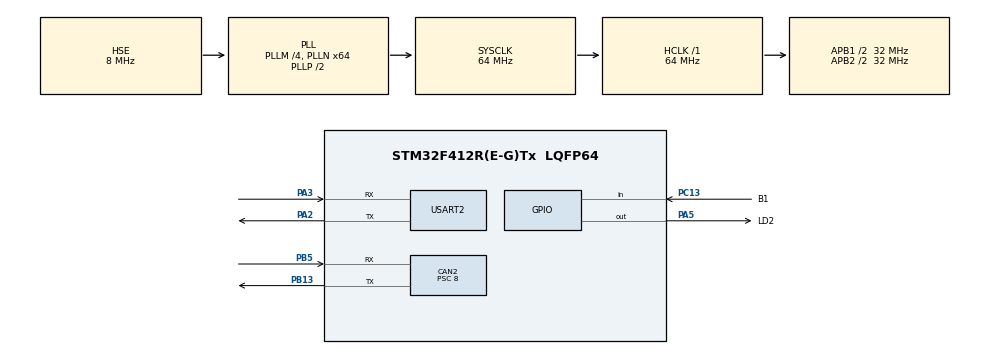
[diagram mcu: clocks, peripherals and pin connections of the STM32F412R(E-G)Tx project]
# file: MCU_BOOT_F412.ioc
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CAN2.ABOM=ENABLE
CAN2.BS1=CAN_BS1_13TQ
CAN2.BS2=CAN_BS2_2TQ
CAN2.CalculateBaudRate=250000
CAN2.CalculateTimeBit=4000
CAN2.CalculateTimeQuantum=250.0
CAN2.NART=DISABLE
CAN2.Prescaler=8
Mcu.Family=STM32F4
Mcu.Name=STM32F412R(E-G)Tx
Mcu.Package=LQFP64
NVIC.PriorityGroup=NVIC_PRIORITYGROUP_4
PA13.Mode=Serial_Wire
PA13.Signal=SYS_JTMS-SWDIO
PA14.Mode=Serial_Wire
PA14.Signal=SYS_JTCK-SWCLK
PA2.Mode=Asynchronous
PA2.Signal=USART2_TX
PA3.Mode=Asynchronous
PA3.Signal=USART2_RX
PA5.GPIO_Label=LD2
PA5.Signal=GPIO_Output
PB13.Mode=CAN_Activate
PB13.Signal=CAN2_TX
PB5.Mode=CAN_Activate
PB5.Signal=CAN2_RX
PC13.GPIO_Label=B1
PC13.GPIO_PuPd=GPIO_PULLUP
PC13.Signal=GPIO_Input
PH0\ -\ OSC_IN.Mode=HSE-External-Oscillator
PH0\ -\ OSC_IN.Signal=RCC_OSC_IN
PH1\ -\ OSC_OUT.Mode=HSE-External-Oscillator
PH1\ -\ OSC_OUT.Signal=RCC_OSC_OUT
ProjectManager.HeapSize=0x200
ProjectManager.StackSize=0x400
ProjectManager.TargetToolchain=STM32CubeIDE
RCC.AHBFreq_Value=64000000
RCC.APB1CLKDivider=RCC_HCLK_DIV2
RCC.APB1Freq_Value=32000000
RCC.APB1TimFreq_Value=64000000
RCC.APB2CLKDivider=RCC_HCLK_DIV2
RCC.APB2Freq_Value=32000000
RCC.APB2TimFreq_Value=64000000
RCC.CortexFreq_Value=64000000
RCC.HCLKFreq_Value=64000000
RCC.HSE_VALUE=8000000
RCC.PLLI2SM=2
RCC.PLLI2SN=64
RCC.PLLM=4
RCC.PLLN=64
RCC.PLLSourceVirtual=RCC_PLLSOURCE_HSE
RCC.SYSCLKFreq_VALUE=64000000
RCC.SYSCLKSource=RCC_SYSCLKSOURCE_PLLCLK
RCC.USBFreq_Value=64000000
RCC.VCOOutputFreq_Value=128000000
USART2.VirtualMode=VM_ASYNC
board=custom

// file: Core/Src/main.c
/* USER CODE BEGIN Header */
/**
  ******************************************************************************
  * @file           : main.c
  * @brief          : Main program body
  ******************************************************************************
  * @attention
  *
  * Copyright (c) 2026 STMicroelectronics.
  * All rights reserved.
  *
  * This software is licensed under terms that can be found in the LICENSE file
  * in the root directory of this software component.
  * If no LICENSE file comes with this software, it is provided AS-IS.
  *
  ******************************************************************************
  */
/* USER CODE END Header */
#include "main.h"

/* USER CODE BEGIN Includes */
#include "boot_port.h"
/* USER CODE END Includes */

CAN_HandleTypeDef hcan2;

UART_HandleTypeDef huart2;

void SystemClock_Config(void);
static void MX_GPIO_Init(void);
static void MX_CAN2_Init(void);
static void MX_USART2_UART_Init(void);

int main(void)
{

  /* MCU Configuration--------------------------------------------------------*/

  /* Reset of all peripherals, Initializes the Flash interface and the Systick. */
  HAL_Init();

  /* Configure the system clock */
  SystemClock_Config();

  /* Initialize all configured peripherals */
  MX_GPIO_Init();
  MX_CAN2_Init();
  MX_USART2_UART_Init();
  /* USER CODE BEGIN 2 */

  /* Runs the CAN receiver, validates and installs updates, then starts the app. */
  boot_run(&hcan2);

  /* USER CODE END 2 */

  /* Infinite loop */
  while (1)
  {

  }
}

void SystemClock_Config(void)
{
  RCC_OscInitTypeDef RCC_OscInitStruct = {0};
  RCC_ClkInitTypeDef RCC_ClkInitStruct = {0};

  /** Configure the main internal regulator output voltage
  */
  __HAL_RCC_PWR_CLK_ENABLE();
  __HAL_PWR_VOLTAGESCALING_CONFIG(PWR_REGULATOR_VOLTAGE_SCALE1);

  /** Initializes the RCC Oscillators according to the specified parameters
  * in the RCC_OscInitTypeDef structure.
  */
  RCC_OscInitStruct.OscillatorType = RCC_OSCILLATORTYPE_HSE;
  RCC_OscInitStruct.HSEState = RCC_HSE_ON;
  RCC_OscInitStruct.PLL.PLLState = RCC_PLL_ON;
  RCC_OscInitStruct.PLL.PLLSource = RCC_PLLSOURCE_HSE;
  RCC_OscInitStruct.PLL.PLLM = 4;
  RCC_OscInitStruct.PLL.PLLN = 64;
  RCC_OscInitStruct.PLL.PLLP = RCC_PLLP_DIV2;
  RCC_OscInitStruct.PLL.PLLQ = 2;
  RCC_OscInitStruct.PLL.PLLR = 2;
  if (HAL_RCC_OscConfig(&RCC_OscInitStruct) != HAL_OK)
  {
    Error_Handler();
  }

  /** Initializes the CPU, AHB and APB buses clocks
  */
  RCC_ClkInitStruct.ClockType = RCC_CLOCKTYPE_HCLK|RCC_CLOCKTYPE_SYSCLK
                              |RCC_CLOCKTYPE_PCLK1|RCC_CLOCKTYPE_PCLK2;
  RCC_ClkInitStruct.SYSCLKSource = RCC_SYSCLKSOURCE_PLLCLK;
  RCC_ClkInitStruct.AHBCLKDivider = RCC_SYSCLK_DIV1;
  RCC_ClkInitStruct.APB1CLKDivider = RCC_HCLK_DIV2;
  RCC_ClkInitStruct.APB2CLKDivider = RCC_HCLK_DIV2;

  if (HAL_RCC_ClockConfig(&RCC_ClkInitStruct, FLASH_LATENCY_1) != HAL_OK)
  {
    Error_Handler();
  }
}

static void MX_CAN2_Init(void)
{

  hcan2.Instance = CAN2;
  hcan2.Init.Prescaler = 8;
  hcan2.Init.Mode = CAN_MODE_NORMAL;
  hcan2.Init.SyncJumpWidth = CAN_SJW_1TQ;
  hcan2.Init.TimeSeg1 = CAN_BS1_13TQ;
  hcan2.Init.TimeSeg2 = CAN_BS2_2TQ;
  hcan2.Init.TimeTriggeredMode = DISABLE;
  hcan2.Init.AutoBusOff = ENABLE;
  hcan2.Init.AutoWakeUp = DISABLE;
  hcan2.Init.AutoRetransmission = DISABLE;
  hcan2.Init.ReceiveFifoLocked = DISABLE;
  hcan2.Init.TransmitFifoPriority = DISABLE;
  if (HAL_CAN_Init(&hcan2) != HAL_OK)
  {
    Error_Handler();
  }

}

static void MX_USART2_UART_Init(void)
{

  huart2.Instance = USART2;
  huart2.Init.BaudRate = 115200;
  huart2.Init.WordLength = UART_WORDLENGTH_8B;
  huart2.Init.StopBits = UART_STOPBITS_1;
  huart2.Init.Parity = UART_PARITY_NONE;
  huart2.Init.Mode = UART_MODE_TX_RX;
  huart2.Init.HwFlowCtl = UART_HWCONTROL_NONE;
  huart2.Init.OverSampling = UART_OVERSAMPLING_16;
  if (HAL_UART_Init(&huart2) != HAL_OK)
  {
    Error_Handler();
  }

}

static void MX_GPIO_Init(void)
{
  GPIO_InitTypeDef GPIO_InitStruct = {0};

  /* GPIO Ports Clock Enable */
  __HAL_RCC_GPIOC_CLK_ENABLE();
  __HAL_RCC_GPIOH_CLK_ENABLE();
  __HAL_RCC_GPIOA_CLK_ENABLE();
  __HAL_RCC_GPIOB_CLK_ENABLE();

  /*Configure GPIO pin Output Level */
  HAL_GPIO_WritePin(LD2_GPIO_Port, LD2_Pin, GPIO_PIN_RESET);

  /*Configure GPIO pin : B1_Pin */
  GPIO_InitStruct.Pin = B1_Pin;
  GPIO_InitStruct.Mode = GPIO_MODE_INPUT;
  GPIO_InitStruct.Pull = GPIO_PULLUP;
  HAL_GPIO_Init(B1_GPIO_Port, &GPIO_InitStruct);

  /*Configure GPIO pin : LD2_Pin */
  GPIO_InitStruct.Pin = LD2_Pin;
  GPIO_InitStruct.Mode = GPIO_MODE_OUTPUT_PP;
  GPIO_InitStruct.Pull = GPIO_NOPULL;
  GPIO_InitStruct.Speed = GPIO_SPEED_FREQ_LOW;
  HAL_GPIO_Init(LD2_GPIO_Port, &GPIO_InitStruct);

}

void Error_Handler(void)
{
  __disable_irq();
  while (1)
  {
  }
}
